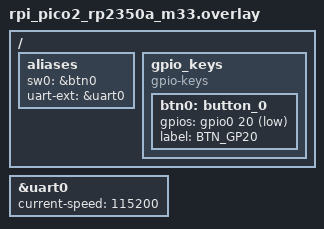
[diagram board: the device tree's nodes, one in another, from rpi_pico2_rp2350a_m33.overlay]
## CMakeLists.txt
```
# Find Zephyr. This also links to Zephyr's build system 
cmake_minimum_required(VERSION 3.20.0)

# set our board 
set(BOARD rpi_pico2/rp2350a/m33)

find_package(Zephyr)

# This is only used by IntelliSense inside VS Code 
set(CMAKE_EXPORT_COMPILE_COMMANDS ON)

# For using west flash with picoprobe
set(OPENOCD "openocd")
set(OPENOCD_DEFAULT_PATH "/usr/local/share/openocd/scripts")

#define project name
project(lab2_part3)

# Add source files
target_include_directories(app PRIVATE src/inc)
FILE(GLOB SRC_FILES "src/*.c")
target_sources(app PRIVATE src/main.c ${SRC_FILES})
```

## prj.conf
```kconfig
CONFIG_GPIO=y
CONFIG_NEWLIB_LIBC=y
CONFIG_NEWLIB_LIBC_FLOAT_PRINTF=y
```

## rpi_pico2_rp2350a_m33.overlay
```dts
/ {
    aliases {
        sw0 = &btn0;
        uart-ext = &uart0;
    };

    gpio_keys {
        compatible = "gpio-keys";

        /* Button on GP20 (GPIO0 controller, pin 20) */
        btn0: button_0 {
            /* Use pull-up, active-low (typical button to GND) */
            gpios = <&gpio0 20 (GPIO_PULL_UP | GPIO_ACTIVE_LOW)>;
            label = "BTN_GP20";
        };
    };
};

&uart0 {
    status = "okay";
    current-speed = <115200>;
};
```

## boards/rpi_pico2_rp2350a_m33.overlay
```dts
/ {
	aliases {
		sw0  = &user_btn0;
	};

	buttons {
		compatible = "gpio-keys";

		user_btn0: user_btn0 {
			gpios = <&gpio0 20 (GPIO_PULL_UP | GPIO_ACTIVE_LOW)>;
			label = "BTN_GP20";
		};
	};
};
```

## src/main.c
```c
#include <zephyr/kernel.h>
#include <zephyr/drivers/gpio.h>
#include <stdio.h>

static const struct gpio_dt_spec button = GPIO_DT_SPEC_GET(DT_ALIAS(sw0), gpios);
static struct gpio_callback button_cb;

static struct k_sem btn_sem;

/* ISR: deferred handling -> only signal */
static void button_isr(const struct device *dev, struct gpio_callback *cb, uint32_t pins)
{
	ARG_UNUSED(dev);
	ARG_UNUSED(cb);
	ARG_UNUSED(pins);

	k_sem_give(&btn_sem); // signal the button task
}

// wait for button press with debounce
static void wait_for_press(void)
{
	k_sem_take(&btn_sem, K_FOREVER); // wait for button press signal
	k_msleep(50);

    while(k_sem_take(&btn_sem, K_NO_WAIT) == 0) {
        // flush any additional presses during debounce period
    }
}

int main(void)
{
	k_sem_init(&btn_sem, 0, 1);

    // configure button with interrupt
	if (!gpio_is_ready_dt(&button)) return 0;
	gpio_pin_configure_dt(&button, GPIO_INPUT);
	gpio_pin_interrupt_configure_dt(&button, GPIO_INT_EDGE_TO_ACTIVE);
	gpio_init_callback(&button_cb, button_isr, BIT(button.pin));
	gpio_add_callback(button.port, &button_cb);

	while (1) {
		printf("\n--- Three second game ---\n");
		printf("Press the button to start the game\n");
		fflush(stdout);

		wait_for_press();
		int64_t t0 = k_uptime_get(); // record start time

		printf("Game Started! Press again after exactly 3.000 seconds...\n");
		fflush(stdout);

		wait_for_press();
		int64_t t1 = k_uptime_get(); // record end time

        // calculate and display results
		int64_t elapsed = t1 - t0;
		int64_t target  = 3000;
		int64_t error   = elapsed - target;
		int64_t abs_err = (error < 0) ? -error : error;
		printf("Your time: %lld ms\n", elapsed);
		printf("Error: %+lld ms (abs %lld ms)\n", error, abs_err);

		// result feedback
		if (abs_err <= 50) {
			printf("Well Done! Very close\n");
		} else if (abs_err <= 150) {
			printf("Close enough\n");
		} else {
			printf("Yikes! Not close\n");
		}
		fflush(stdout);
	}
}
```
